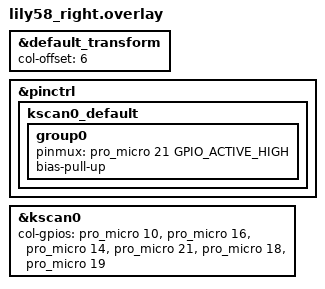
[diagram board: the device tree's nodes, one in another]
/*
 * Copyright (c) 2020 Pete Johanson
 *
 * SPDX-License-Identifier: MIT
 */

#include "lily58.dtsi"

&default_transform {
    col-offset = <6>;
};
&pinctrl {
    kscan0_default: kscan0_default {
        group0 {
            pinmux = <&pro_micro 21 GPIO_ACTIVE_HIGH>;
            bias-pull-up;
        };
    };
};

&kscan0 {
    col-gpios
        = <&pro_micro 10 GPIO_ACTIVE_HIGH>
        , <&pro_micro 16 GPIO_ACTIVE_HIGH>
        , <&pro_micro 14 GPIO_ACTIVE_HIGH>
        , <&pro_micro 21 GPIO_ACTIVE_HIGH>
        , <&pro_micro 18 GPIO_ACTIVE_HIGH>
        , <&pro_micro 19 GPIO_ACTIVE_HIGH>
        ;
};
